# AT32UC3A4128S device description
Architecture: AVR32_UC3; Family: AVR UC3
Registers are 32-bit, read-write, reset 0x0 unless marked. A register's access mark holds for its fields unless they carry their own. Offsets are from the block's base; [hi:lo] are bit positions; {n}, {i} and the like mark numbered series; 'fields as' and 'values as' point back to an identical list.

## DMACA — DMA Controller
Instances: DMACA 0xff100000
{0x0+0x58*i} SAR{i} (i=0..3) — Channel {i} Source Address Register
  [31:0] SADD — Source Address of DMA transfer
{0x8+0x58*i} DAR{i} (i=0..3) — Channel {i} Destination Address Register
  [31:0] DADD — Destination Address of DMA transfer
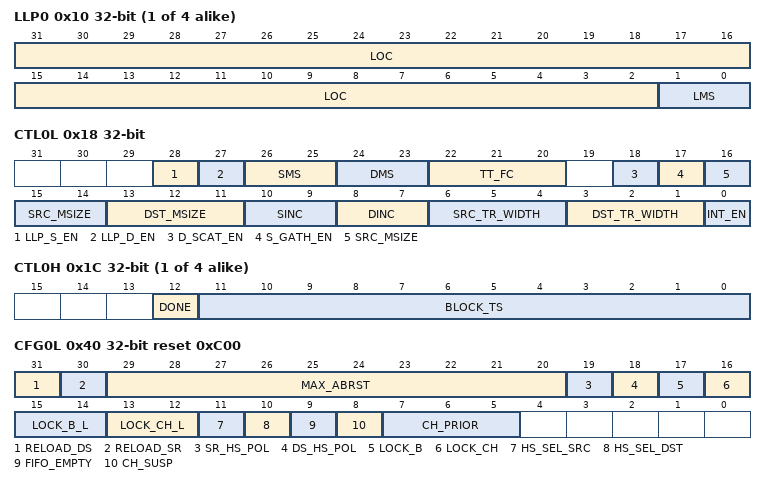
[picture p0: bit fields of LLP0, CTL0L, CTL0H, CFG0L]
{0x10+0x58*i} LLP{i} (i=0..3) — Channel {i} Linked List Pointer Register
  [31:2] LOC — Starting Address in Memory.
  [1:0] LMS — List Master Select.
0x18 CTL0L — Channel 0 Control Register Low
  [28] LLP_S_EN
  [27] LLP_D_EN
  [26:25] SMS
  [24:23] DMS
  [22:20] TT_FC
  [18] D_SCAT_EN
  [17] S_GATH_EN
  [16:14] SRC_MSIZE
  [13:11] DST_MSIZE
  [10:9] SINC
  [8:7] DINC — Destination Address Increment
  [6:4] SRC_TR_WIDTH
  [3:1] DST_TR_WIDTH
  [0] INT_EN
{0x1C+0x58*i} CTL{i}H (i=0..3) — Channel {i} Control Register High
  [12] DONE, [11:0] BLOCK_TS
0x40 CFG0L reset 0xC00 — Channel 0 Configuration Register Low
  [31] RELOAD_DS, [30] RELOAD_SR, [29:20] MAX_ABRST, [19] SR_HS_POL, [18] DS_HS_POL, [17] LOCK_B, [16] LOCK_CH, [15:14] LOCK_B_L, [13:12] LOCK_CH_L, [11] HS_SEL_SRC, [10] HS_SEL_DST, [9] FIFO_EMPTY, [8] CH_SUSP, [7:5] CH_PRIOR
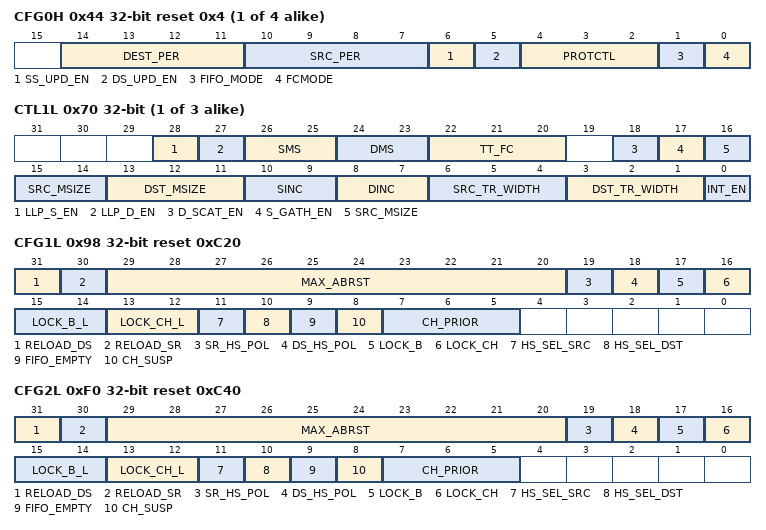
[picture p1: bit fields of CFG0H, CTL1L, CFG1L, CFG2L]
{0x44+0x58*i} CFG{i}H reset 0x4 (i=0..3) — Channel {i} Configuration Register High
  [14:11] DEST_PER, [10:7] SRC_PER, [6] SS_UPD_EN, [5] DS_UPD_EN, [4:2] PROTCTL, [1] FIFO_MODE, [0] FCMODE
{0x18+0x58*i} CTL{i}L (i=1..3) — Channel {i} Control Register Low
  [28] LLP_S_EN, [27] LLP_D_EN, [26:25] SMS, [24:23] DMS, [22:20] TT_FC, [18] D_SCAT_EN, [17] S_GATH_EN, [16:14] SRC_MSIZE, [13:11] DST_MSIZE, [10:9] SINC, [8:7] DINC, [6:4] SRC_TR_WIDTH, [3:1] DST_TR_WIDTH, [0] INT_EN
0x98 CFG1L reset 0xC20 — Channel 1 Configuration Register Low
  fields as CFG0L
0xF0 CFG2L reset 0xC40 — Channel 2 Configuration Register Low
  fields as CFG0L
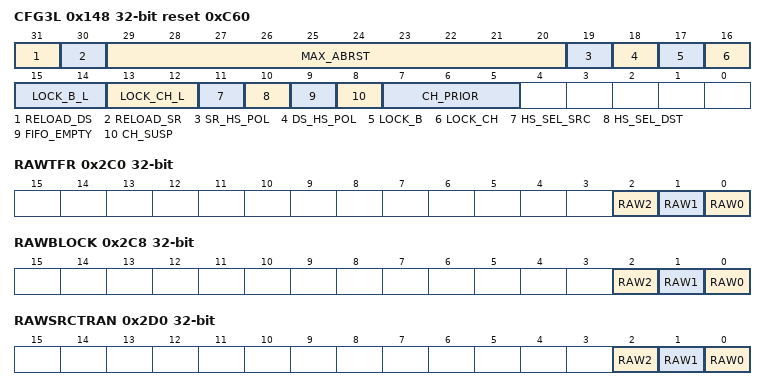
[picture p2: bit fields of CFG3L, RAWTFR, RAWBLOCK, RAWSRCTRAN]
0x148 CFG3L reset 0xC60 — Channel 3 Configuration Register Low
  fields as CFG0L
0x2C0 RAWTFR ro — Raw status for IntTfr Interrupt
  [2] RAW2, [1] RAW1, [0] RAW0
0x2C8 RAWBLOCK ro — Raw status for IntBlock Interrupt
  [2] RAW2, [1] RAW1, [0] RAW0
0x2D0 RAWSRCTRAN ro — Raw status for IntSrcTran Interrupt
  [2] RAW2, [1] RAW1, [0] RAW0
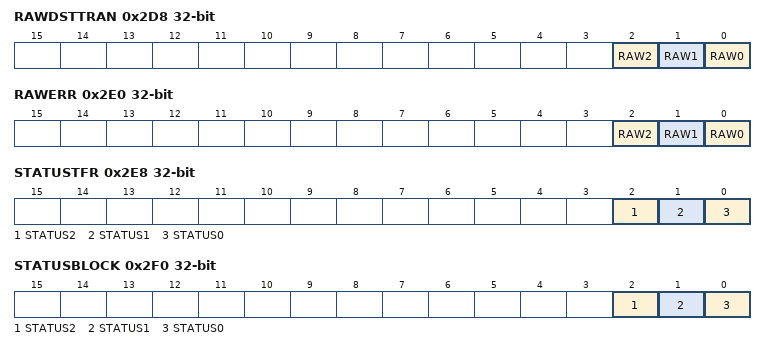
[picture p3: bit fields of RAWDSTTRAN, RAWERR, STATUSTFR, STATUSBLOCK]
0x2D8 RAWDSTTRAN ro — Raw status for IntDstTran Interrupt
  [2] RAW2, [1] RAW1, [0] RAW0
0x2E0 RAWERR ro — Raw status for IntErr Interrupt
  [2] RAW2, [1] RAW1, [0] RAW0
0x2E8 STATUSTFR ro — Status for IntTfr Interrupt
  [2] STATUS2, [1] STATUS1, [0] STATUS0
0x2F0 STATUSBLOCK ro — Status for IntBlock Interrupt
  [2] STATUS2, [1] STATUS1, [0] STATUS0
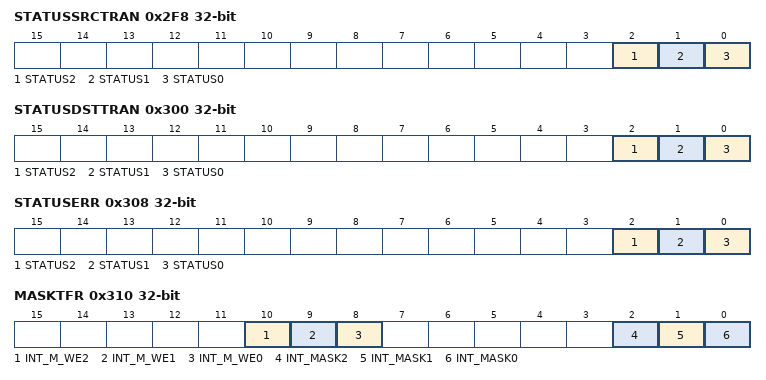
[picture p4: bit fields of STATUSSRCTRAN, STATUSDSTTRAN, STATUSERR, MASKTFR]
0x2F8 STATUSSRCTRAN ro — Status for IntSrcTran Interrupt
  [2] STATUS2, [1] STATUS1, [0] STATUS0
0x300 STATUSDSTTRAN ro — Status for IntDstTran Interrupt
  [2] STATUS2, [1] STATUS1, [0] STATUS0
0x308 STATUSERR ro — Status for IntErr Interrupt
  [2] STATUS2, [1] STATUS1, [0] STATUS0
0x310 MASKTFR — Mask for IntTfr Interrupt
  [10] INT_M_WE2, [9] INT_M_WE1, [8] INT_M_WE0, [2] INT_MASK2, [1] INT_MASK1, [0] INT_MASK0
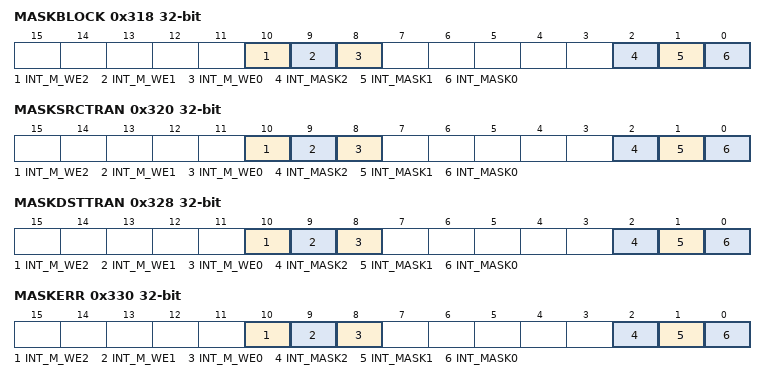
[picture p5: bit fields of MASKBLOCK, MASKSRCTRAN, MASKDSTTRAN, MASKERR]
0x318 MASKBLOCK — Mask for IntBlock Interrupt
  fields as MASKTFR
0x320 MASKSRCTRAN — Mask for IntSrcTran Interrupt
  fields as MASKTFR
0x328 MASKDSTTRAN — Mask for IntDstTran Interrupt
  fields as MASKTFR
0x330 MASKERR — Mask for IntErr Interrupt
  fields as MASKTFR
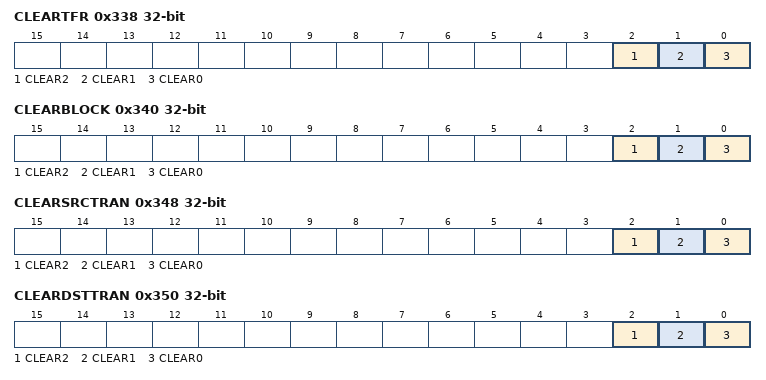
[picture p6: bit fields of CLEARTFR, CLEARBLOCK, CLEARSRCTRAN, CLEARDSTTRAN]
0x338 CLEARTFR wo — Clear for IntTfr Interrupt
  [2] CLEAR2, [1] CLEAR1, [0] CLEAR0
0x340 CLEARBLOCK wo — Clear for IntBlock Interrupt
  [2] CLEAR2, [1] CLEAR1, [0] CLEAR0
0x348 CLEARSRCTRAN wo — Clear for IntSrcTran Interrupt
  [2] CLEAR2, [1] CLEAR1, [0] CLEAR0
0x350 CLEARDSTTRAN wo — Clear for IntDstTran Interrupt
  [2] CLEAR2, [1] CLEAR1, [0] CLEAR0
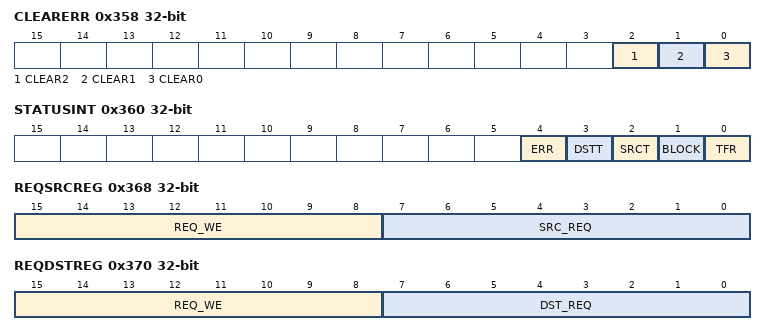
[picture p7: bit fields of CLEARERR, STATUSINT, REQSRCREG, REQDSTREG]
0x358 CLEARERR wo — Clear for IntErr Interrupt
  [2] CLEAR2, [1] CLEAR1, [0] CLEAR0
0x360 STATUSINT ro — Status for each interrupt type
  [4] ERR, [3] DSTT, [2] SRCT, [1] BLOCK, [0] TFR
0x368 REQSRCREG — Source Software Transaction Request Register
  [15:8] REQ_WE, [7:0] SRC_REQ
0x370 REQDSTREG — Destination Software Transaction Request Register
  [15:8] REQ_WE, [7:0] DST_REQ
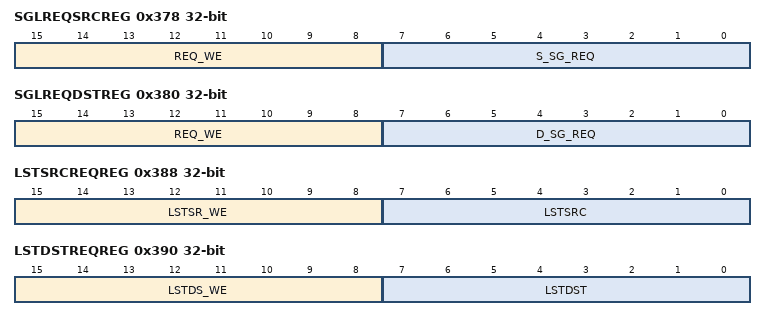
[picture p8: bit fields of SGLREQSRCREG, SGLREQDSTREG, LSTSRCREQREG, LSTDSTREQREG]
0x378 SGLREQSRCREG — Single Source Transaction Request Register
  [15:8] REQ_WE, [7:0] S_SG_REQ
0x380 SGLREQDSTREG — Single Destination Transaction Request Register
  [15:8] REQ_WE, [7:0] D_SG_REQ
0x388 LSTSRCREQREG — Last Source Transaction Request Register
  [15:8] LSTSR_WE, [7:0] LSTSRC
0x390 LSTDSTREQREG — Last Destination Transaction Request Register
  [15:8] LSTDS_WE, [7:0] LSTDST
0x398 DMACFGREG — DMA Configuration Register
  [0] DMA_EN
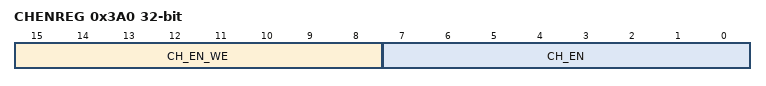
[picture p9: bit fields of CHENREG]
0x3A0 CHENREG — DMA Channel Enable Register
  [15:8] CH_EN_WE, [7:0] CH_EN
0x3A8 IDREG — DMA ID Register
0x3B0 DMATESTREG — DMA Test Register
  [0] TEST_SLV_IF
